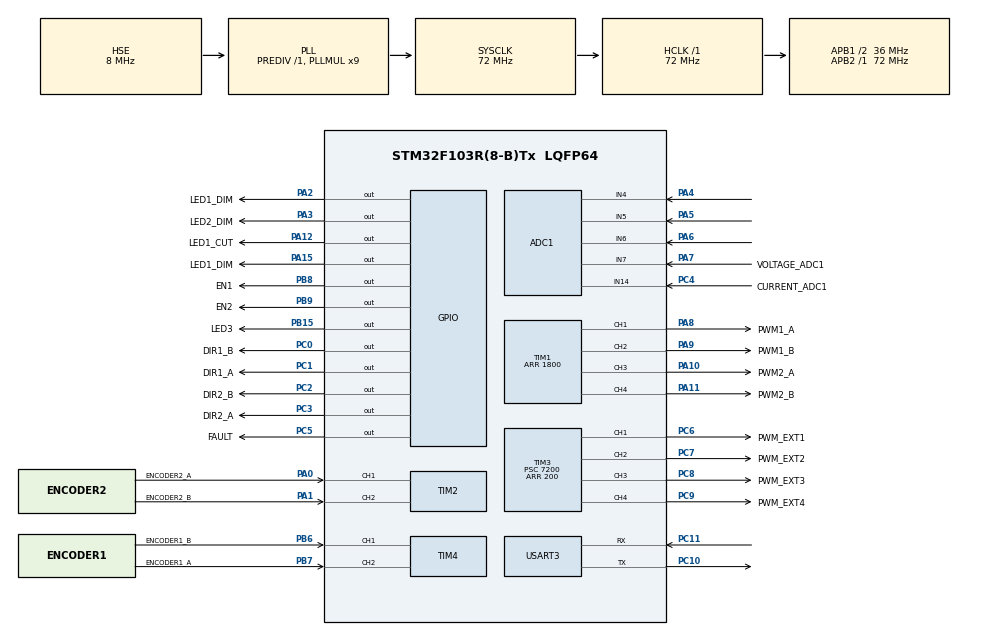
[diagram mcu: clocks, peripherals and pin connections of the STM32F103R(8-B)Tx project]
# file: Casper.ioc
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ADC1.Channel-2\#ChannelRegularConversion=ADC_CHANNEL_14
ADC1.Channel-3\#ChannelRegularConversion=ADC_CHANNEL_7
ADC1.ContinuousConvMode=ENABLE
ADC1.NbrOfConversion=2
ADC1.NbrOfConversionFlag=1
ADC1.Rank-2\#ChannelRegularConversion=1
ADC1.Rank-3\#ChannelRegularConversion=2
ADC1.SamplingTime-2\#ChannelRegularConversion=ADC_SAMPLETIME_1CYCLE_5
ADC1.SamplingTime-3\#ChannelRegularConversion=ADC_SAMPLETIME_1CYCLE_5
ADC1.master=1
Dma.ADC1.0.Direction=DMA_PERIPH_TO_MEMORY
Dma.ADC1.0.Instance=DMA1_Channel1
Dma.ADC1.0.MemDataAlignment=DMA_MDATAALIGN_HALFWORD
Dma.ADC1.0.MemInc=DMA_MINC_ENABLE
Dma.ADC1.0.Mode=DMA_CIRCULAR
Dma.ADC1.0.PeriphDataAlignment=DMA_PDATAALIGN_HALFWORD
Dma.ADC1.0.PeriphInc=DMA_PINC_DISABLE
Dma.ADC1.0.Priority=DMA_PRIORITY_LOW
Dma.Request0=ADC1
Dma.Request1=USART3_TX
Dma.USART3_TX.1.Direction=DMA_MEMORY_TO_PERIPH
Dma.USART3_TX.1.Instance=DMA1_Channel2
Dma.USART3_TX.1.MemDataAlignment=DMA_MDATAALIGN_BYTE
Dma.USART3_TX.1.MemInc=DMA_MINC_ENABLE
Dma.USART3_TX.1.Mode=DMA_NORMAL
Dma.USART3_TX.1.PeriphDataAlignment=DMA_PDATAALIGN_BYTE
Dma.USART3_TX.1.PeriphInc=DMA_PINC_DISABLE
Dma.USART3_TX.1.Priority=DMA_PRIORITY_LOW
Mcu.Family=STM32F1
Mcu.Name=STM32F103R(8-B)Tx
Mcu.Package=LQFP64
NVIC.DMA1_Channel1_IRQn=true\:0\:0\:false\:false\:true\:false\:true
NVIC.DMA1_Channel2_IRQn=true\:0\:0\:false\:false\:true\:false\:true
NVIC.PriorityGroup=NVIC_PRIORITYGROUP_4
NVIC.TIM1_UP_IRQn=true\:15\:0\:false\:false\:true\:true\:true
NVIC.TIM2_IRQn=true\:0\:0\:false\:false\:true\:true\:true
NVIC.USART3_IRQn=true\:0\:0\:false\:false\:true\:true\:true
PA0-WKUP.GPIO_Label=ENCODER2_A
PA0-WKUP.Signal=S_TIM2_CH1_ETR
PA1.GPIO_Label=ENCODER2_B
PA1.Signal=S_TIM2_CH2
PA10.GPIO_Label=PWM2_A
PA10.Signal=S_TIM1_CH3
PA11.GPIO_Label=PWM2_B
PA11.Signal=S_TIM1_CH4
PA12.GPIO_Label=LED1_CUT
PA12.Signal=GPIO_Output
PA13.Mode=Serial_Wire
PA13.Signal=SYS_JTMS-SWDIO
PA14.Mode=Serial_Wire
PA14.Signal=SYS_JTCK-SWCLK
PA15.GPIO_Label=LED1_DIM
PA15.Signal=GPIO_Output
PA2.GPIO_Label=LED1_DIM
PA2.Signal=GPIO_Output
PA3.GPIO_Label=LED2_DIM
PA3.Signal=GPIO_Output
PA4.Signal=ADCx_IN4
PA5.Signal=ADCx_IN5
PA6.Signal=ADCx_IN6
PA7.GPIO_Label=VOLTAGE_ADC1
PA7.Signal=ADCx_IN7
PA8.GPIO_Label=PWM1_A
PA8.Signal=S_TIM1_CH1
PA9.GPIO_Label=PWM1_B
PA9.Signal=S_TIM1_CH2
PB15.GPIO_Label=LED3
PB15.Signal=GPIO_Output
PB6.GPIO_Label=ENCODER1_B
PB6.Signal=S_TIM4_CH1
PB7.GPIO_Label=ENCODER1_A
PB7.Signal=S_TIM4_CH2
PB8.GPIO_Label=EN1
PB8.Signal=GPIO_Output
PB9.GPIO_Label=EN2
PB9.Signal=GPIO_Output
PC0.GPIO_Label=DIR1_B
PC0.Signal=GPIO_Output
PC1.GPIO_Label=DIR1_A
PC1.Signal=GPIO_Output
PC10.Mode=Asynchronous
PC10.Signal=USART3_TX
PC11.Mode=Asynchronous
PC11.Signal=USART3_RX
PC2.GPIO_Label=DIR2_B
PC2.Signal=GPIO_Output
PC3.GPIO_Label=DIR2_A
PC3.Signal=GPIO_Output
PC4.GPIO_Label=CURRENT_ADC1
PC4.Signal=ADCx_IN14
PC5.GPIO_Label=FAULT
PC5.Signal=GPIO_Output
PC6.GPIO_Label=PWM_EXT1
PC6.Signal=S_TIM3_CH1
PC7.GPIO_Label=PWM_EXT2
PC7.Signal=S_TIM3_CH2
PC8.GPIO_Label=PWM_EXT3
PC8.Signal=S_TIM3_CH3
PC9.GPIO_Label=PWM_EXT4
PC9.Signal=S_TIM3_CH4
PD0-OSC_IN.Mode=HSE-External-Oscillator
PD0-OSC_IN.Signal=RCC_OSC_IN
PD1-OSC_OUT.Mode=HSE-External-Oscillator
PD1-OSC_OUT.Signal=RCC_OSC_OUT
ProjectManager.HeapSize=0x200
ProjectManager.StackSize=0x400
ProjectManager.TargetToolchain=STM32CubeIDE
RCC.ADCPresc=RCC_ADCPCLK2_DIV6
RCC.AHBFreq_Value=72000000
RCC.APB1CLKDivider=RCC_HCLK_DIV2
RCC.APB1Freq_Value=36000000
RCC.APB1TimFreq_Value=72000000
RCC.APB2Freq_Value=72000000
RCC.APB2TimFreq_Value=72000000
RCC.HCLKFreq_Value=72000000
RCC.PLLMUL=RCC_PLL_MUL9
RCC.PLLSourceVirtual=RCC_PLLSOURCE_HSE
RCC.SYSCLKFreq_VALUE=72000000
RCC.SYSCLKSource=RCC_SYSCLKSOURCE_PLLCLK
RCC.USBFreq_Value=72000000
SH.ADCx_IN14.0=ADC1_IN14,IN14
SH.ADCx_IN4.0=ADC1_IN4,IN4
SH.ADCx_IN5.0=ADC1_IN5,IN5
SH.ADCx_IN6.0=ADC1_IN6,IN6
SH.ADCx_IN7.0=ADC1_IN7,IN7
SH.S_TIM1_CH1.0=TIM1_CH1,Output Compare1 CH1
SH.S_TIM1_CH2.0=TIM1_CH2,Output Compare2 CH2
SH.S_TIM1_CH3.0=TIM1_CH3,Output Compare3 CH3
SH.S_TIM1_CH4.0=TIM1_CH4,Output Compare4 CH4
SH.S_TIM2_CH1_ETR.0=TIM2_CH1,Encoder_Interface
SH.S_TIM2_CH2.0=TIM2_CH2,Encoder_Interface
SH.S_TIM3_CH1.0=TIM3_CH1,Output Compare1 CH1
SH.S_TIM3_CH2.0=TIM3_CH2,Output Compare2 CH2
SH.S_TIM3_CH3.0=TIM3_CH3,Output Compare3 CH3
SH.S_TIM3_CH4.0=TIM3_CH4,Output Compare4 CH4
SH.S_TIM4_CH1.0=TIM4_CH1,Encoder_Interface
SH.S_TIM4_CH2.0=TIM4_CH2,Encoder_Interface
TIM1.Channel-Output\ Compare1\ CH1=TIM_CHANNEL_1
TIM1.Channel-Output\ Compare2\ CH2=TIM_CHANNEL_2
TIM1.Channel-Output\ Compare3\ CH3=TIM_CHANNEL_3
TIM1.Channel-Output\ Compare4\ CH4=TIM_CHANNEL_4
TIM1.ClockDivision=TIM_CLOCKDIVISION_DIV4
TIM1.OCMode_1=TIM_OCMODE_ACTIVE
TIM1.OCMode_2=TIM_OCMODE_ACTIVE
TIM1.Period=1800
TIM2.EncoderMode=TIM_ENCODERMODE_TI12
TIM2.IC1Polarity=TIM_ICPOLARITY_FALLING
TIM2.IC2Polarity=TIM_ICPOLARITY_FALLING
TIM3.Channel-Output\ Compare1\ CH1=TIM_CHANNEL_1
TIM3.Channel-Output\ Compare2\ CH2=TIM_CHANNEL_2
TIM3.Channel-Output\ Compare3\ CH3=TIM_CHANNEL_3
TIM3.Channel-Output\ Compare4\ CH4=TIM_CHANNEL_4
TIM3.Period=200
TIM3.Prescaler=7200
USART3.VirtualMode=VM_ASYNC
VP_ADC1_TempSens_Input.Mode=IN-TempSens
VP_TIM1_VS_ClockSourceINT.Mode=Internal
board=custom

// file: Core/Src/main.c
/* USER CODE BEGIN Header */
/**
  ******************************************************************************
  * @file           : main.c
  * @brief          : Main program body
  ******************************************************************************
  * @attention
  *
  * Copyright (c) 2021 STMicroelectronics.
  * All rights reserved.
  *
  * This software is licensed under terms that can be found in the LICENSE file
  * in the root directory of this software component.
  * If no LICENSE file comes with this software, it is provided AS-IS.
  *
  ******************************************************************************
  */
/* USER CODE END Header */
#include "main.h"
#include "adc.h"
#include "dma.h"
#include "tim.h"
#include "usart.h"
#include "gpio.h"

/* USER CODE BEGIN Includes */
#include "communication.h"
#include "motor_control.h"
/* USER CODE END Includes */

void SystemClock_Config(void);

int main(void)
{

  /* MCU Configuration--------------------------------------------------------*/

  /* Reset of all peripherals, Initializes the Flash interface and the Systick. */
  HAL_Init();

  /* Configure the system clock */
  SystemClock_Config();

  /* Initialize all configured peripherals */
  MX_GPIO_Init();
  MX_ADC1_Init();
  MX_USART3_UART_Init();
  MX_TIM1_Init();
  MX_TIM2_Init();
  MX_TIM3_Init();
  MX_DMA_Init();
  MX_TIM4_Init();
  /* USER CODE BEGIN 2 */
  HAL_TIM_Encoder_Start_IT(&htim2, TIM_CHANNEL_ALL);
  /* USER CODE END 2 */

  /* Infinite loop */
  /* USER CODE BEGIN WHILE */
  while (1)
  {
	  if(is_new_frame_availible()){
		  uint8_t buffer[UART_MAX_RX_LEGHT];
		  uint8_t lenght = get_new_frame(buffer);
		  switch (buffer[1]) {
			case '!':{
				deserialize_motor_control_frame(buffer, lenght);
				break;
			}
			default:
				break;
		}
	  }
    /* USER CODE END WHILE */

  }
}

void SystemClock_Config(void)
{
  RCC_OscInitTypeDef RCC_OscInitStruct = {0};
  RCC_ClkInitTypeDef RCC_ClkInitStruct = {0};
  RCC_PeriphCLKInitTypeDef PeriphClkInit = {0};

  /** Initializes the RCC Oscillators according to the specified parameters
  * in the RCC_OscInitTypeDef structure.
  */
  RCC_OscInitStruct.OscillatorType = RCC_OSCILLATORTYPE_HSE;
  RCC_OscInitStruct.HSEState = RCC_HSE_ON;
  RCC_OscInitStruct.HSEPredivValue = RCC_HSE_PREDIV_DIV1;
  RCC_OscInitStruct.HSIState = RCC_HSI_ON;
  RCC_OscInitStruct.PLL.PLLState = RCC_PLL_ON;
  RCC_OscInitStruct.PLL.PLLSource = RCC_PLLSOURCE_HSE;
  RCC_OscInitStruct.PLL.PLLMUL = RCC_PLL_MUL9;
  if (HAL_RCC_OscConfig(&RCC_OscInitStruct) != HAL_OK)
  {
    Error_Handler();
  }
  /** Initializes the CPU, AHB and APB buses clocks
  */
  RCC_ClkInitStruct.ClockType = RCC_CLOCKTYPE_HCLK|RCC_CLOCKTYPE_SYSCLK
                              |RCC_CLOCKTYPE_PCLK1|RCC_CLOCKTYPE_PCLK2;
  RCC_ClkInitStruct.SYSCLKSource = RCC_SYSCLKSOURCE_PLLCLK;
  RCC_ClkInitStruct.AHBCLKDivider = RCC_SYSCLK_DIV1;
  RCC_ClkInitStruct.APB1CLKDivider = RCC_HCLK_DIV2;
  RCC_ClkInitStruct.APB2CLKDivider = RCC_HCLK_DIV1;

  if (HAL_RCC_ClockConfig(&RCC_ClkInitStruct, FLASH_LATENCY_2) != HAL_OK)
  {
    Error_Handler();
  }
  PeriphClkInit.PeriphClockSelection = RCC_PERIPHCLK_ADC;
  PeriphClkInit.AdcClockSelection = RCC_ADCPCLK2_DIV6;
  if (HAL_RCCEx_PeriphCLKConfig(&PeriphClkInit) != HAL_OK)
  {
    Error_Handler();
  }
}

void Error_Handler(void)
{
  __disable_irq();
  while (1)
  {
  }
}
